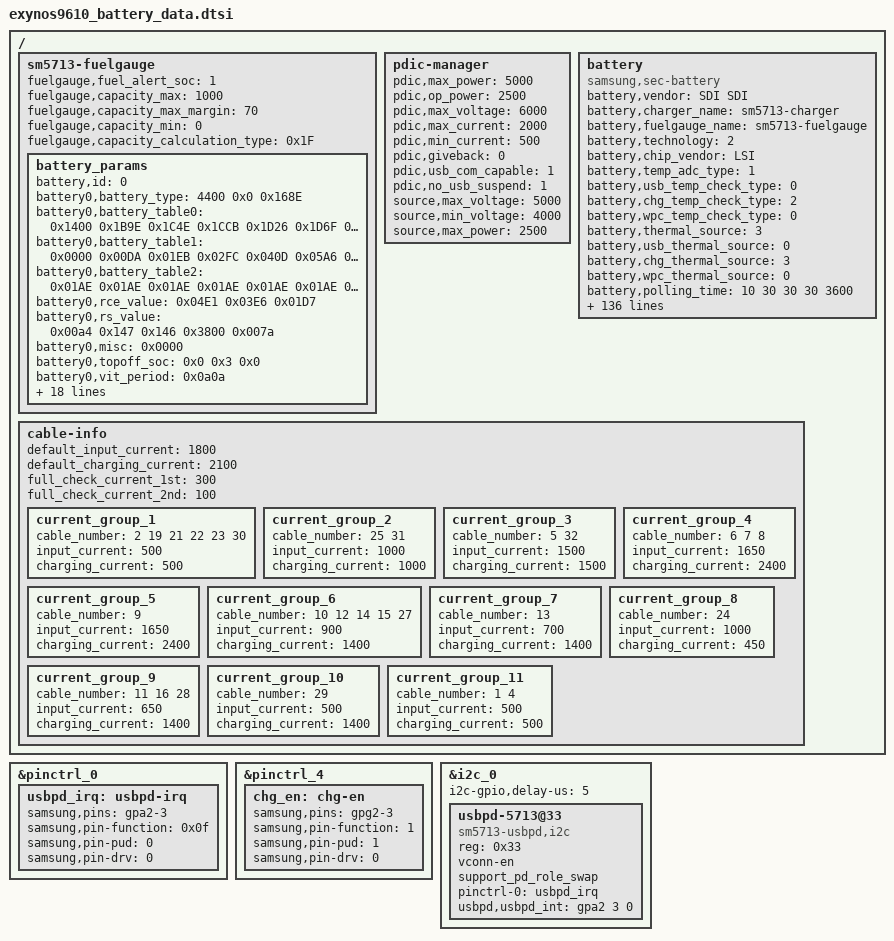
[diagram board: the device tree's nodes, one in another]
/*
 * SAMSUNG UNIVERSAL9610 board device tree source
 *
 * Copyright (c) 2013 Samsung Electronics Co., Ltd.
 *		http://www.samsung.com
 *
 * This program is free software; you can redistribute it and/or modify
 * it under the terms of the GNU General Public License version 2 as
 * published by the Free Software Foundation.
 */

/ {
	fragment@battery {
		target-path = "/";
		__overlay__ {
			sm5713-fuelgauge {
				status = "okay";
				fuelgauge,fuel_alert_soc = <1>;
				fuelgauge,capacity_max = <1000>;
				fuelgauge,capacity_max_margin = <70>;
				fuelgauge,capacity_min = <0>;
				fuelgauge,capacity_calculation_type = <0x1F>;
				battery_params {
					battery,id = <0>;
					battery0,battery_type = <4400 0x0 0x168E>; /* 4200 or 4350 or 4400*/
					battery0,battery_table0 = <0x1400 0x1B9E 0x1C4E 0x1CCB 0x1D26 0x1D6F 0x1D86 0x1DA0 0x1DDF 0x1E04 0x1E2D 0x1E4C 0x1E68 0x1E8A 0x1EB5 0x1EEC 0x1F14 0x1F56 0x1FB0 0x1FFF 0x2091 0x2146 0x2236 0x2400>;
					battery0,battery_table1 = <0x0000 0x00DA 0x01EB 0x02FC 0x040D 0x05A6 0x0AFB 0x0DA5 0x12FA 0x184E 0x1DA3 0x22F7 0x284C 0x2DA1 0x32F5 0x384A 0x3AF4 0x3D9E 0x42F3 0x4848 0x5046 0x5956 0x6400 0x644C>;
					battery0,battery_table2 = <0x01AE 0x01AE 0x01AE 0x01AE 0x01AE 0x01AE 0x01AE 0x01AE 0x01AE 0x01AE 0x01AE 0x01AE 0x01AE 0x01AE 0x01AE 0x01AE>;
					battery0,rce_value = <0x04E1 0x03E6 0x01D7>;
					battery0,rs_value = <0x00a4 0x147 0x146 0x3800 0x007a>; /*rs p_mix_factor, n_mix_factor max min*/
					battery0,misc = <0x0000>;
					battery0,topoff_soc = <0x0 0x3 0x0>; /*disable soc*/
					battery0,vit_period = <0x0a0a>;
					battery0,dtcd_value = <0x1>;
					battery0,volt_cal = <0x8000>;
					battery0,curr_offset = <1 0 0 0 0 0 0>;
					battery0,mix_value = <0x0103 0x0004>; /*mix_rate init_blank*/
					battery0,temp_std = <25>;
					battery0,temp_cal = <0 6 1 11 (-1) 1 6 1 9 1>;
					battery0,ext_temp_cal = <0 2 1 2 1 1 2 3 2 3>;
					battery0,temp_volcal = <1 15 1>;
					battery0,temp_offset = <1 11 1 1 8 (-1)>;
					battery0,curr_cal = <0x8080 0x8080 0x8080 0x8080 0x8080 0x8080>;
					battery0,tem_poff = <3400 50 3250 50>;
					battery0,arsm = <1 3 1 0x6>;
					battery0,cycle_cfg = <0 0 0>;
					battery0,full_offset = <0 0>;
					battery0,v_offset_cancel = <0 0 100 10>;
					battery0,v_alarm = <3100 0>;
					battery0,data_ver = <1>;
				};
			};

			pdic-manager {
				/* sink */
				pdic,max_power = <5000>;
				pdic,op_power = <2500>;
				pdic,max_voltage = <6000>;
				pdic,max_current = <2000>;
				pdic,min_current = <500>;

				pdic,giveback = <0>;
				pdic,usb_com_capable = <1>;
				pdic,no_usb_suspend = <1>;

				/* source */
				source,max_voltage = <5000>;
				source,min_voltage = <4000>;
				source,max_power = <2500>;
			};

			battery {
				status = "okay";
				compatible = "samsung,sec-battery";

				pinctrl-names = "default";

				battery,vendor = "SDI SDI";
				battery,charger_name = "sm5713-charger";
				battery,fuelgauge_name = "sm5713-fuelgauge";
				battery,technology = <2>; /* POWER_SUPPLY_TECHNOLOGY_LION */

				battery,chip_vendor = "LSI";
				battery,temp_adc_type = <1>; /* SEC_BATTERY_ADC_TYPE_AP */

				battery,usb_temp_check_type = <0>; /* SEC_BATTERY_TEMP_CHECK_NONE */
				battery,chg_temp_check_type = <2>; /* SEC_BATTERY_TEMP_CHECK_TEMP */
				battery,wpc_temp_check_type = <0>; /* SEC_BATTERY_TEMP_CHECK_NONE */
				battery,thermal_source = <3>; /* SEC_BATTERY_THERMAL_SOURCE_ADC */
				battery,usb_thermal_source = <0>; /* SEC_BATTERY_THERMAL_SOURCE_NONE */
				battery,chg_thermal_source = <3>; /* SEC_BATTERY_THERMAL_SOURCE_ADC */
				battery,wpc_thermal_source = <0>; /* SEC_BATTERY_THERMAL_SOURCE_NONE */

				battery,polling_time = <10 30 30 30 3600>;

				battery,temp_table_adc = <236 308 389 475 543 622 674 767 821 903 1049 1208 1332 1405 1481 1590 1816 2026
					2253 2493 2629 2718 2809 2939 3115 3306 3431 3569 3676>;
				battery,temp_table_data = <900 850 800 750 700 650 620 600 580 550 500 450 420 400 380 350 300 250
					200 150 120 100 80 50 0 (-50) (-100) (-150) (-200)>;

				battery,chg_temp_table_adc = <236 308 376 449 509 581 593 760 816 901 1046 1211 1334 1405 1482 1586 1790 2001
					2217 2445 2570 2655 2740 2858 3046 3199 3335 3453 3537>;
				battery,chg_temp_table_data = <900 850 800 750 700 650 620 600 580 550 500 450 420 400 380 350 300 250
					200 150 120 100 80 50 0 (-50) (-100) (-150) (-200)>;

				battery,input_current_limit = <1800 450 450 1800 500 900 1500 450 1000 450 900 900 900 1900 1800 450 450 400 700 1300 300 1000 1500 450 1650 2100 500 1650 80 1800 1650 1400 1000 1000 700 900 900 900 500 1800 1650 3000>;
				battery,fast_charging_current = <2100 450 450 2100 800 1200 1500 450 1200 450 2100 2100 2100 1600 2100 450 450 400 700 1300 300 1000 1500 450 2400 3500 500 2400 80 1800 1000 1400 450 1000 2100 2100 2100 2100 450 2100 2400 3000>;
				battery,full_check_current_1st = <300 0 0 300 300 300 300 300 300 0 300 300 300 300 300 0 0 300 300 300 300 300 300 0 300 300 300 300 0 300 300 300 0 300 300 300 300 300 300 300 300 300>;
				battery,full_check_current_2nd = <100 0 0 100 100 100 100 100 100 0 100 100 100 100 100 0 0 100 100 100 100 100 100 0 100 100 100 100 0 100 100 100 0 100 100 100 100 100 100 100 100 100>;

				battery,wireless_cc_cv = <85>;
				battery,inbat_voltage = <1>;

				battery,inbat_voltage_table_adc = <2817 2803 2783 2753 2728 2701 2680 2654 2628 2597
					2565 2536 2509 2478 2450 2426 2401 2372 2343 2321 2290>;
				battery,inbat_voltage_table_data = <4383 4352 4306 4253 4204 4152 4101 4053 4002 3954
					3903 3852 3801 3750 3702 3654 3601 3552 3503 3456 3402>;

				battery,adc_check_count = <5>;

				battery,cable_check_type = <4>; /* SEC_BATTERY_CABLE_CHECK_PSY */
				battery,cable_source_type = <1>; /* SEC_BATTERY_CABLE_SOURCE_EXTERNAL */
				battery,polling_type = <1>; /* SEC_BATTERY_MONITOR_ALARM */
				battery,monitor_initial_count = <0>;

				battery,pre_afc_input_current = <500>;

				battery,battery_check_type = <0>; /* SEC_BATTERY_CHECK_NONE */
				battery,check_count = <0>;
				battery,check_adc_max = <1440>;
				battery,check_adc_min = <0>;

				battery,ovp_uvlo_check_type = <3>; /* SEC_BATTERY_OVP_UVLO_CHGPOLLING */

				battery,temp_check_type = <2>; /* SEC_BATTERY_TEMP_CHECK_TEMP */
				battery,temp_check_count = <1>;
				battery,temp_highlimit_threshold_normal = <800>;
				battery,temp_highlimit_recovery_normal = <750>;
				battery,temp_high_threshold_normal = <500>;
				battery,temp_high_recovery_normal = <450>;
				battery,temp_low_threshold_normal = <0>;
				battery,temp_low_recovery_normal = <50>;
				battery,temp_highlimit_threshold_lpm = <800>;
				battery,temp_highlimit_recovery_lpm = <750>;
				battery,temp_high_threshold_lpm = <500>;
				battery,temp_high_recovery_lpm = <450>;
				battery,temp_low_threshold_lpm = <0>;
				battery,temp_low_recovery_lpm = <50>;

				battery,full_check_type = <2>; /* SEC_BATTERY_FULLCHARGED_FG_CURRENT */
				battery,full_check_type_2nd = <2>; /* SEC_BATTERY_FULLCHARGED_FG_CURRENT */
				battery,full_check_count = <1>;
				battery,chg_gpio_full_check = <0>;
				battery,chg_polarity_full_check = <1>;

				battery,chg_heating_prevention_method = <1>; /* SEC_BATTERY_BY_CHANGING_CURRENT */
				battery,chg_12v_high_temp = <615>;
				battery,chg_high_temp = <465>;
				battery,chg_high_temp_recovery = <460>;
				battery,chg_charging_limit_current = <1100>;

				battery,wpc_high_temp = <460 495>;
				battery,wpc_high_temp_recovery = <459 400>;
				battery,wpc_charging_limit_current = <540 400>;
				battery,wpc_heat_temp_recovery = <360>;
				battery,wpc_lcd_on_high_temp = <470>;
				battery,wpc_lcd_on_high_temp_rec = <300>;
				battery,wpc_hv_lcd_on_input_limit_current = <400>;

				battery,sleep_mode_limit_current = <500>;
				battery,wc_full_input_limit_current = <100>;
				battery,wc_heating_input_limit_current = <400>;
				battery,wc_heating_time = <300>; /* 5 min */
				battery,wc_cv_current = <820>;
				battery,wc_cv_pack_current = <630>;

				battery,mix_high_temp = <420>;
				battery,mix_high_chg_temp = <500>;
				battery,mix_high_temp_recovery = <390>;

				/* SEC_BATTERY_FULL_CONDITION_SOC |
				   SEC_BATTERY_FULL_CONDITION_NOTIMEFULL |
				   SEC_BATTERY_FULL_CONDITION_VCELL */
				battery,full_condition_type = <13>;
				battery,full_condition_soc = <93>;
				battery,full_condition_vcell = <4250>;

				battery,recharge_check_count = <1>;
				battery,recharge_condition_type = <4>; /* SEC_BATTERY_RECHARGE_CONDITION_VCELL */
				battery,recharge_condition_soc = <98>;
				battery,recharge_condition_vcell = <4300>;

				battery,charging_total_time = <21600>;
				battery,recharging_total_time = <5400>;
				battery,charging_reset_time = <0>;

				battery,chg_float_voltage = <4350>;

				battery,swelling_high_temp_block = <410>;
				battery,swelling_high_temp_recov = <360>;
				battery,swelling_low_temp_block = <100>;
				battery,swelling_low_temp_recov = <150>;
				battery,swelling_low_temp_additional = <50>;

				battery,swelling_low_temp_current = <1350>;	/* 0.45C */
				battery,swelling_low_temp_additional_current = <525>;	/* 0.18C 540mA -> 525mA */
				battery,swelling_low_temp_topoff = <150>;	/* 0.05C */
				battery,swelling_high_temp_current = <1350>;	/* 0.45C */
				battery,swelling_high_temp_topoff = <150>;	/* 0.05C */

				battery,swelling_drop_float_voltage = <4150>;
				battery,swelling_high_rechg_voltage = <4100>;
				battery,swelling_low_rechg_voltage = <4000>;

				battery,self_discharging_temp_block = <600>;
				battery,self_discharging_volt_block = <4250>;
				battery,self_discharging_temp_recov = <550>;
				battery,self_discharging_temp_pollingtime = <400>;

				battery,siop_event_check_type = <1>;
				battery,siop_call_cv_current = <330>;
				battery,siop_call_cc_current = <330>;

				battery,siop_input_limit_current = <1200>;
				battery,siop_charging_limit_current = <1000>;
				battery,siop_hv_input_limit_current = <700>;
				battery,siop_hv_charging_limit_current = <1200>;
				battery,siop_hv_12v_input_limit_current = <535>;
				battery,siop_hv_12v_charging_limit_current = <1000>;

				battery,siop_wireless_input_limit_current = <600>;
				battery,siop_wireless_charging_limit_current = <1000>;
				battery,siop_hv_wireless_input_limit_current = <600>;
				battery,siop_hv_wireless_charging_limit_current = <1000>;

				battery,ttf_hv_12v_charge_current = <2350>;
				battery,ttf_hv_charge_current = <2200>;
				battery,ttf_hv_wireless_charge_current = <1500>;

				/* cycle, chg_float_voltage, recharge_condition_vcell, full_condition_vcell, full_condition_soc */
				battery,age_data = <0 43625 4312 4275 93
					300 43250 4275 4210 89
					500 42875 4237 4170 85>;

				/* values for using CONFIG_STEP_CHARGING */
				battery,step_charging_type = <0x5>;
				battery,step_charging_charge_power = <20000>;
				battery,step_charging_condtion = <4100 4400>;
				battery,step_charging_current = <4200 3000>;
				/* values for not using CONFIG_STEP_CHARGING */
				battery,base_charge_power = <15000>;
				battery,max_charging_current = <2400>;

				battery,max_input_voltage = <9000>; /* mV */
				battery,max_input_current = <3000>;  /* mA */

				battery,prepare_afc_delay = <0>;

				io-channels = <&exynos_adc 1>, <&exynos_adc 2>, <&exynos_adc 3>;
				io-channel-names = "adc-temp", "adc-in-bat", "adc-chg-temp";
				#io-channel-cells = <5>;
				io-channel-ranges;
			};

		/* sec_battery_cable
		 *   0	UNKNOWN,
		 *   1	NONE,
		 *   2	PREPARE_TA,
		 *   3	TA,
		 *   4	USB,
		 *   5	USB_CDP,
		 *   6	9V_TA,
		 *   7	9V_ERR,
		 *   8	9V_UNKNOWN,
		 *   9	12V_TA,
		 *  10	WIRELESS,
		 *  11	HV_WIRELESS,
		 *  12	PMA_WIRELESS,
		 *  13	WIRELESS_PACK,
		 *  14	WIRELESS_PACK_TA,
		 *  15	WIRELESS_STAND,
		 *  16	WIRELESS_HV_STAND,
		 *  17	QC20,
		 *  18	QC30,
		 *  19	PDIC,
		 *  20	UARTOFF,
		 *  21	OTG,
		 *  22	LAN_HUB,
		 *  23	POWER_SHARING,
		 *  24	HMT_CONNECTED,
		 *  25	HMT_CHARGE,
		 *  26	HV_TA_CHG_LIMIT,
		 *  27	WIRELESS_VEHICLE,
		 *  28	WIRELESS_HV_VEHICLE,
		 *  29	PREPARE_WIRELESS_HV,
		 *  30	TIMEOUT,
		 *  31	SMART_OTG,
		 *  32	SMART_NOTG,
		 *  33	CABLE_MAX,
		 */
			cable-info {
				default_input_current = <1800>;
				default_charging_current = <2100>;
				full_check_current_1st = <300>;
				full_check_current_2nd = <100>;

				current_group_1 {
					cable_number = <2 19 21 22 23 30>;
					input_current = <500>;
					charging_current = <500>;
				};
				current_group_2 {
					cable_number = <25 31>;
					input_current = <1000>;
					charging_current = <1000>;
				};
				current_group_3 {
					cable_number = <5 32>;
					input_current = <1500>;
					charging_current = <1500>;
				};
				current_group_4 {
					cable_number = <6 7 8>;
					input_current = <1650>;
					charging_current = <2400>;
				};
				current_group_5 {
					cable_number = <9>;
					input_current = <1650>;
					charging_current = <2400>;
				};
				current_group_6 {
					cable_number = <10 12 14 15 27>;
					input_current = <900>;
					charging_current = <1400>;
				};
				current_group_7 {
					cable_number = <13>;
					input_current = <700>;
					charging_current = <1400>;
				};
				current_group_8 {
					cable_number = <24>;
					input_current = <1000>;
					charging_current = <450>;
				};
				current_group_9 {
					cable_number = <11 16 28>;
					input_current = <650>;
					charging_current = <1400>;
				};
				current_group_10 {
					cable_number = <29>;
					input_current = <500>;
					charging_current = <1400>;
				};
				current_group_11 {
					cable_number = <1 4>;
					input_current = <500>;
					charging_current = <500>;
				};
			};
		};
	};
};

&pinctrl_0 {
	usbpd_irq: usbpd-irq {
		samsung,pins = "gpa2-3";
		samsung,pin-function = <0x0f>;
		samsung,pin-pud = <0>;
		samsung,pin-drv = <0>;
	};
};

&pinctrl_4 {
	chg_en: chg-en {
		samsung,pins = "gpg2-3";
		samsung,pin-function = <1>;
		samsung,pin-pud = <1>;
		samsung,pin-drv = <0>;
	};
};

&i2c_0 {
	i2c-gpio,delay-us = <5>;
	status = "okay";
	#address-cells = <1>;
	#size-cells = <0>;
	usbpd-5713@33 {
		compatible = "sm5713-usbpd,i2c";
		reg = <0x33>;
		pinctrl-names = "default";
		vconn-en;
		support_pd_role_swap;
		pinctrl-0 = <&usbpd_irq>;
		usbpd,usbpd_int = <&gpa2 3 0>;
	};
};
